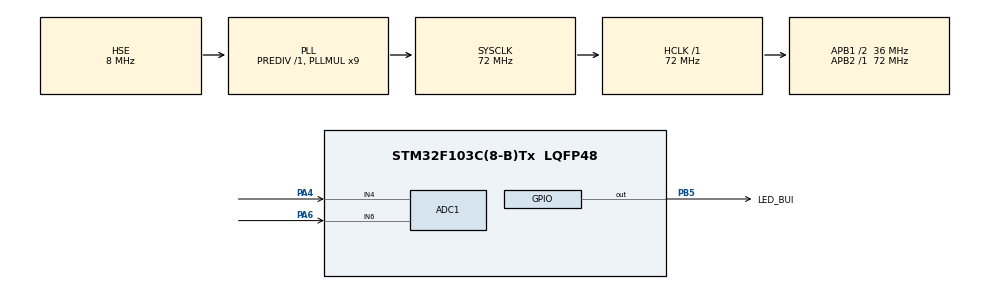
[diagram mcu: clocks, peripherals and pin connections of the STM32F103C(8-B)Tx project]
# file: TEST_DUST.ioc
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Mcu.Family=STM32F1
RCC.PLLSourceVirtual=RCC_PLLSOURCE_HSE
Dma.ADC1.0.Instance=DMA1_Channel1
ADC1.Rank-0\#ChannelRegularConversion=1
PD1-OSC_OUT.Mode=HSE-External-Oscillator
SH.ADCx_IN6.0=ADC1_IN6,IN6
PD0-OSC_IN.Signal=RCC_OSC_IN
RCC.APB1CLKDivider=RCC_HCLK_DIV2
RCC.SYSCLKSource=RCC_SYSCLKSOURCE_PLLCLK
ProjectManager.StackSize=0x400
PD1-OSC_OUT.Signal=RCC_OSC_OUT
RCC.ADCPresc=RCC_ADCPCLK2_DIV6
PA13.Signal=SYS_JTMS-SWDIO
Dma.ADC1.0.PeriphDataAlignment=DMA_PDATAALIGN_WORD
TIM1.Prescaler=72-1
ProjectManager.TargetToolchain=STM32CubeIDE
Dma.ADC1.0.Mode=DMA_CIRCULAR
RCC.HCLKFreq_Value=72000000
Dma.ADC1.0.Priority=DMA_PRIORITY_LOW
RCC.APB2TimFreq_Value=72000000
Dma.ADC1.0.Direction=DMA_PERIPH_TO_MEMORY
RCC.USBFreq_Value=72000000
Dma.ADC1.0.MemDataAlignment=DMA_MDATAALIGN_WORD
RCC.AHBFreq_Value=72000000
PD0-OSC_IN.Mode=HSE-External-Oscillator
ADC1.Channel-0\#ChannelRegularConversion=ADC_CHANNEL_6
board=custom
RCC.PLLMUL=RCC_PLL_MUL9
RCC.APB2Freq_Value=72000000
PA14.Mode=Serial_Wire
Dma.ADC1.0.PeriphInc=DMA_PINC_DISABLE
SH.ADCx_IN4.0=ADC1_IN4,IN4
ADC1.NbrOfConversion=1
PA13.Mode=Serial_Wire
Mcu.Name=STM32F103C(8-B)Tx
VP_TIM1_VS_ClockSourceINT.Mode=Internal
ADC1.SamplingTime-0\#ChannelRegularConversion=ADC_SAMPLETIME_239CYCLES_5
PA4.Signal=ADCx_IN4
RCC.SYSCLKFreq_VALUE=72000000
Mcu.Package=LQFP48
PB5.Signal=GPIO_Output
PA6.Signal=ADCx_IN6
ADC1.master=1
PA14.Signal=SYS_JTCK-SWCLK
Dma.ADC1.0.MemInc=DMA_MINC_ENABLE
ProjectManager.HeapSize=0x200
NVIC.PriorityGroup=NVIC_PRIORITYGROUP_4
ADC1.NbrOfConversionFlag=1
PB5.GPIO_Label=LED_BUI
RCC.APB1TimFreq_Value=72000000
TIM1.Period=0xffff-1
NVIC.DMA1_Channel1_IRQn=true\:0\:0\:false\:false\:true\:false\:true
Dma.Request0=ADC1
RCC.APB1Freq_Value=36000000

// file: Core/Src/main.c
/* USER CODE BEGIN Header */
/**
 ******************************************************************************
 * @file           : main.c
 * @brief          : Main program body
 ******************************************************************************
 * @attention
 *
 * <h2><center>&copy; Copyright (c) 2023 STMicroelectronics.
 * All rights reserved.</center></h2>
 *
 * This software component is licensed by ST under BSD 3-Clause license,
 * the "License"; You may not use this file except in compliance with the
 * License. You may obtain a copy of the License at:
 *                        opensource.org/licenses/BSD-3-Clause
 *
 ******************************************************************************
 */
/* USER CODE END Header */
#include "main.h"

ADC_HandleTypeDef hadc1;
DMA_HandleTypeDef hdma_adc1;

TIM_HandleTypeDef htim1;

void SystemClock_Config(void);
static void MX_GPIO_Init(void);
static void MX_DMA_Init(void);
static void MX_ADC1_Init(void);
static void MX_TIM1_Init(void);

/* USER CODE BEGIN 0 */
uint32_t value_Adc;
uint16_t value_Adc_Gp2y10;
#define SharpGP2Y10_SAMPLINGTIME 280
uint16_t dustDensity;
float voltage;
void microDelay(uint16_t delay) {
	__HAL_TIM_SET_COUNTER(&htim1, 0);
	while (__HAL_TIM_GET_COUNTER(&htim1) < delay)
		;
}

uint16_t Filter(uint16_t m) {
	static uint16_t flag_first = 0, _buff[10], sum;
	const uint16_t _buff_max = 10;
	int i;
	if (flag_first == 0) {
		flag_first = 1;
		for (i = 0, sum = 0; i < _buff_max; i++) {
			_buff[i] = m;
			sum += _buff[i];
		}
		return m;
	} else {
		sum -= _buff[0];
		for (i = 0; i < (_buff_max - 1); i++) {
			_buff[i] = _buff[i + 1];
		}
		_buff[9] = m;
		sum += _buff[9];

		i = sum / 10.0;
		return i;
	}
}
uint16_t value_Gp2y10(uint16_t value) {
	uint16_t value_Dust;
	value = Filter(value);
	voltage = (3300 / 4096.0) * value * 11;
	value_Dust = 0.17 * voltage - 0.1;
	return value_Dust;
}
/* USER CODE END 0 */

int main(void)
{

  /* MCU Configuration--------------------------------------------------------*/

  /* Reset of all peripherals, Initializes the Flash interface and the Systick. */
  HAL_Init();

  /* Configure the system clock */
  SystemClock_Config();

  /* Initialize all configured peripherals */
  MX_GPIO_Init();
  MX_DMA_Init();
  MX_ADC1_Init();
  MX_TIM1_Init();
  /* USER CODE BEGIN 2 */
	HAL_TIM_Base_Start(&htim1);
	HAL_ADCEx_Calibration_Start(&hadc1);
  /* USER CODE END 2 */

  /* Infinite loop */
  /* USER CODE BEGIN WHILE */
	while (1) {
		HAL_GPIO_WritePin(LED_BUI_GPIO_Port, LED_BUI_Pin, GPIO_PIN_SET);
		microDelay(SharpGP2Y10_SAMPLINGTIME);		// delay 0.28ms
		HAL_ADC_Start_DMA(&hadc1, &value_Adc, 1);
		HAL_GPIO_WritePin(LED_BUI_GPIO_Port, LED_BUI_Pin, GPIO_PIN_RESET);
		dustDensity = value_Gp2y10(value_Adc);
		HAL_Delay(1000);
    /* USER CODE END WHILE */

	}
}

void SystemClock_Config(void)
{
  RCC_OscInitTypeDef RCC_OscInitStruct = {0};
  RCC_ClkInitTypeDef RCC_ClkInitStruct = {0};
  RCC_PeriphCLKInitTypeDef PeriphClkInit = {0};

  /** Initializes the RCC Oscillators according to the specified parameters
  * in the RCC_OscInitTypeDef structure.
  */
  RCC_OscInitStruct.OscillatorType = RCC_OSCILLATORTYPE_HSE;
  RCC_OscInitStruct.HSEState = RCC_HSE_ON;
  RCC_OscInitStruct.HSEPredivValue = RCC_HSE_PREDIV_DIV1;
  RCC_OscInitStruct.HSIState = RCC_HSI_ON;
  RCC_OscInitStruct.PLL.PLLState = RCC_PLL_ON;
  RCC_OscInitStruct.PLL.PLLSource = RCC_PLLSOURCE_HSE;
  RCC_OscInitStruct.PLL.PLLMUL = RCC_PLL_MUL9;
  if (HAL_RCC_OscConfig(&RCC_OscInitStruct) != HAL_OK)
  {
    Error_Handler();
  }
  /** Initializes the CPU, AHB and APB buses clocks
  */
  RCC_ClkInitStruct.ClockType = RCC_CLOCKTYPE_HCLK|RCC_CLOCKTYPE_SYSCLK
                              |RCC_CLOCKTYPE_PCLK1|RCC_CLOCKTYPE_PCLK2;
  RCC_ClkInitStruct.SYSCLKSource = RCC_SYSCLKSOURCE_PLLCLK;
  RCC_ClkInitStruct.AHBCLKDivider = RCC_SYSCLK_DIV1;
  RCC_ClkInitStruct.APB1CLKDivider = RCC_HCLK_DIV2;
  RCC_ClkInitStruct.APB2CLKDivider = RCC_HCLK_DIV1;

  if (HAL_RCC_ClockConfig(&RCC_ClkInitStruct, FLASH_LATENCY_2) != HAL_OK)
  {
    Error_Handler();
  }
  PeriphClkInit.PeriphClockSelection = RCC_PERIPHCLK_ADC;
  PeriphClkInit.AdcClockSelection = RCC_ADCPCLK2_DIV6;
  if (HAL_RCCEx_PeriphCLKConfig(&PeriphClkInit) != HAL_OK)
  {
    Error_Handler();
  }
}

static void MX_ADC1_Init(void)
{

  ADC_ChannelConfTypeDef sConfig = {0};

  /** Common config
  */
  hadc1.Instance = ADC1;
  hadc1.Init.ScanConvMode = ADC_SCAN_DISABLE;
  hadc1.Init.ContinuousConvMode = DISABLE;
  hadc1.Init.DiscontinuousConvMode = DISABLE;
  hadc1.Init.ExternalTrigConv = ADC_SOFTWARE_START;
  hadc1.Init.DataAlign = ADC_DATAALIGN_RIGHT;
  hadc1.Init.NbrOfConversion = 1;
  if (HAL_ADC_Init(&hadc1) != HAL_OK)
  {
    Error_Handler();
  }
  /** Configure Regular Channel
  */
  sConfig.Channel = ADC_CHANNEL_6;
  sConfig.Rank = ADC_REGULAR_RANK_1;
  sConfig.SamplingTime = ADC_SAMPLETIME_239CYCLES_5;
  if (HAL_ADC_ConfigChannel(&hadc1, &sConfig) != HAL_OK)
  {
    Error_Handler();
  }

}

static void MX_TIM1_Init(void)
{

  TIM_ClockConfigTypeDef sClockSourceConfig = {0};
  TIM_MasterConfigTypeDef sMasterConfig = {0};

  htim1.Instance = TIM1;
  htim1.Init.Prescaler = 72-1;
  htim1.Init.CounterMode = TIM_COUNTERMODE_UP;
  htim1.Init.Period = 0xffff-1;
  htim1.Init.ClockDivision = TIM_CLOCKDIVISION_DIV1;
  htim1.Init.RepetitionCounter = 0;
  htim1.Init.AutoReloadPreload = TIM_AUTORELOAD_PRELOAD_DISABLE;
  if (HAL_TIM_Base_Init(&htim1) != HAL_OK)
  {
    Error_Handler();
  }
  sClockSourceConfig.ClockSource = TIM_CLOCKSOURCE_INTERNAL;
  if (HAL_TIM_ConfigClockSource(&htim1, &sClockSourceConfig) != HAL_OK)
  {
    Error_Handler();
  }
  sMasterConfig.MasterOutputTrigger = TIM_TRGO_RESET;
  sMasterConfig.MasterSlaveMode = TIM_MASTERSLAVEMODE_DISABLE;
  if (HAL_TIMEx_MasterConfigSynchronization(&htim1, &sMasterConfig) != HAL_OK)
  {
    Error_Handler();
  }

}

static void MX_DMA_Init(void)
{

  /* DMA controller clock enable */
  __HAL_RCC_DMA1_CLK_ENABLE();

  /* DMA interrupt init */
  /* DMA1_Channel1_IRQn interrupt configuration */
  HAL_NVIC_SetPriority(DMA1_Channel1_IRQn, 0, 0);
  HAL_NVIC_EnableIRQ(DMA1_Channel1_IRQn);

}

static void MX_GPIO_Init(void)
{
  GPIO_InitTypeDef GPIO_InitStruct = {0};

  /* GPIO Ports Clock Enable */
  __HAL_RCC_GPIOD_CLK_ENABLE();
  __HAL_RCC_GPIOA_CLK_ENABLE();
  __HAL_RCC_GPIOB_CLK_ENABLE();

  /*Configure GPIO pin Output Level */
  HAL_GPIO_WritePin(LED_BUI_GPIO_Port, LED_BUI_Pin, GPIO_PIN_RESET);

  /*Configure GPIO pin : LED_BUI_Pin */
  GPIO_InitStruct.Pin = LED_BUI_Pin;
  GPIO_InitStruct.Mode = GPIO_MODE_OUTPUT_PP;
  GPIO_InitStruct.Pull = GPIO_NOPULL;
  GPIO_InitStruct.Speed = GPIO_SPEED_FREQ_LOW;
  HAL_GPIO_Init(LED_BUI_GPIO_Port, &GPIO_InitStruct);

}

void Error_Handler(void)
{
	__disable_irq();
	while (1) {
	}
}

/************************ (C) COPYRIGHT STMicroelectronics *****END OF FILE****/
